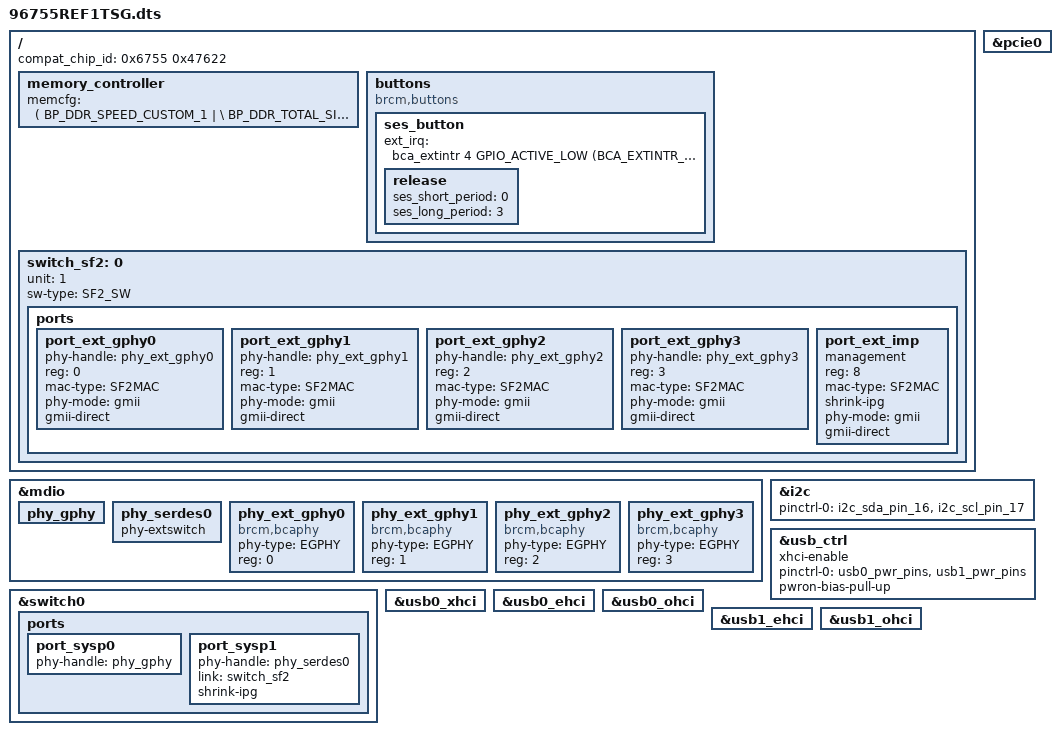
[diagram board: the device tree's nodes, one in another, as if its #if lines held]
#include "47622.dtsi"

/ {
	compat_chip_id = <0x6755 0x47622>;
    memory_controller {
        memcfg = <(
                   /* CUSTOM speed 1026MHz */
	               BP_DDR_SPEED_CUSTOM_1      | \
                   BP_DDR_TOTAL_SIZE_512MB    | \
                   BP_DDR_DEVICE_WIDTH_16     | \
                   BP_DDR_TOTAL_WIDTH_16BIT   | \
                   BP_DDR_SSC_CONFIG_1)>;
    };

	buttons {
		compatible = "brcm,buttons";
		ses_button {
			ext_irq = <&bca_extintr 4 GPIO_ACTIVE_LOW (BCA_EXTINTR_TYPE_LOW_LEVEL | BCA_EXTINTR_TYPE_SENSE_EDGE)>;
			release {
				ses_short_period = <0>;
				ses_long_period = <3>;
			};
		};
	};

	switch_sf2:0 {
	};
};


&mdio {
    /* Port PHY mapping:
            port_sysp0 <---> phy_gphy
            port_sysp1 <---> phy_serdes0 <--> port_ext_imp -8#0- port_ext_gphy0 <--> phy_ext_gphy0
                                                            # 1- port_ext_gphy1 <--> phy_ext_gphy1
                                                            # 2- port_ext_gphy2 <--> phy_ext_gphy2
                                                            ##3- port_ext_gphy3 <--> phy_ext_gphy3
     */
	phy_gphy {
		status = "okay";
	};

	phy_serdes0 {
		phy-extswitch;
		status = "okay";
	};

	/* PHYs on external SF2 switch */
	phy_ext_gphy0:phy_ext_gphy0 {
		compatible = "brcm,bcaphy";
		phy-type = "EGPHY";
		reg = <0>;
		status = "okay";
	};
	phy_ext_gphy1:phy_ext_gphy1 {
		compatible = "brcm,bcaphy";
		phy-type = "EGPHY";
		reg = <1>;
		status = "okay";
	};
	phy_ext_gphy2:phy_ext_gphy2 {
		compatible = "brcm,bcaphy";
		phy-type = "EGPHY";
		reg = <2>;
		status = "okay";
	};
	phy_ext_gphy3:phy_ext_gphy3 {
		compatible = "brcm,bcaphy";
		phy-type = "EGPHY";
		reg = <3>;
		status = "okay";
	};
};

&switch_sf2 {
	unit = <1>;
	sw-type = "SF2_SW";

	ports {
		#address-cells = <1>;
		#size-cells = <0>;

		port_ext_gphy0 {
			phy-handle = <&phy_ext_gphy0>;
			reg = <0>;
			mac-type = "SF2MAC";
			phy-mode = "gmii";
			gmii-direct;
			status = "okay";
		};
		port_ext_gphy1 {
			phy-handle = <&phy_ext_gphy1>;
			reg = <1>;
			mac-type = "SF2MAC";
			phy-mode = "gmii";
			gmii-direct;
			status = "okay";
		};
		port_ext_gphy2 {
			phy-handle = <&phy_ext_gphy2>;
			reg = <2>;
			mac-type = "SF2MAC";
			phy-mode = "gmii";
			gmii-direct;
			status = "okay";
		};
		port_ext_gphy3 {
			phy-handle = <&phy_ext_gphy3>;
			reg = <3>;
			mac-type = "SF2MAC";
			phy-mode = "gmii";
			gmii-direct;
			status = "okay";
		};
		port_ext_imp {
			management;                     /* sf2.p8 <--> sysp.p1 */
			reg = <8>;
			mac-type = "SF2MAC";
			shrink-ipg;
			phy-mode = "gmii";
			gmii-direct;
			status = "okay";
		};
	};
};

&switch0 {
	ports {
		/* fixed port configuration */
		port_sysp0 {
			phy-handle = <&phy_gphy>;
			status = "okay";
		};
		port_sysp1 {
			phy-handle = <&phy_serdes0>;
			link = <&switch_sf2>;           /* sysp.p1 <--> sf2.p8 */
			shrink-ipg;
			status = "okay";
		};
	};
};

#if defined(CONFIG_BCM_PCIE_HCD) || defined (CONFIG_BCM_PCIE_HCD_MODULE)
&pcie0 {
	status = "okay";
};
#endif

&i2c {
	pinctrl-names = "default";
	pinctrl-0 = <&i2c_sda_pin_16 &i2c_scl_pin_17>;
	status = "okay";
};

&usb_ctrl {
	status = "okay";
	xhci-enable;
	pinctrl-names = "default";
	pinctrl-0 = <&usb0_pwr_pins &usb1_pwr_pins>;
	pwron-bias-pull-up;
};

&usb0_xhci {
	status = "okay";
};

&usb0_ehci {
	status = "okay";
};

&usb0_ohci {
	status = "okay";
};

&usb1_ehci {
	status = "okay";
};

&usb1_ohci {
	status = "okay";
};

